AUTOSAR XML (schema 4-3-1)
package /TPC_Composition/Components
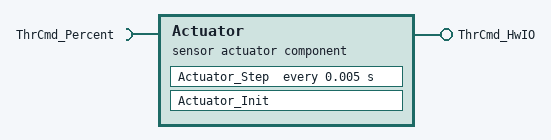
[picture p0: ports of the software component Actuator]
  sensor actuator sw component type Actuator
    require port ThrCmd_Percent: nonqueued-receiver-com-spec{data-element=Value, init-value=0}, required-interface=ThrCmd_Percent
    provide port ThrCmd_HwIO: nonqueued-sender-com-spec{data-element=Value, init-value=0}, provided-interface=ThrCmd_HwIO
    behavior Actuator_IB: data-type-mapping=ActuatorDataTypeMappingsSet, handle-termination-and-restart=NO-SUPPORT
      timing event Event_Actuator_Step: start-on-event=Actuator_Step, period=0.005
      runnable Actuator_Init
      runnable Actuator_Step
        data-read-access:
          access IN_ThrCmd_Percent_Value: accessed-variable=ThrCmd_Percent.Value
        data-write-access:
          access OUT_ThrCmd_HwIO_Value: accessed-variable=ThrCmd_HwIO.Value
        parameter access SCALPRM_HBridgeCmd_LkupTbl: accessed-parameter=HBridgeCmd_LkupTbl, sw-calprm-axis-set={sw-axis-index=1, sw-axis-individual=sw-variable=ThrCmd_Percent.Value}
      shared-parameters:
        parameter data prototype HBridgeCmd_LkupTbl: category=CURVE, sw-calibration-access=READ-WRITE, type=Appl_HBridgeCmd_LkupTbl, init-value=constant-reference={short-label=HBridgeCmd_LkupTbl, constant=HBridgeCmd_LkupTbl}
